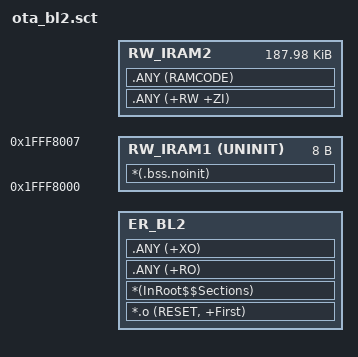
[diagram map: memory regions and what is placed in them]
#! armclang -E --target=arm-arm-none-eabi -mcpu=cortex-m4 -xc
#include "ota_layout.h"
LR_BL2 NTN_OTA_BL2_BASE NTN_OTA_BL2_SIZE {
    ER_BL2 NTN_OTA_BL2_BASE {
        *.o (RESET, +First)
        *(InRoot$$Sections)
        .ANY (+RO)
        .ANY (+XO)
    }
    RW_IRAM1 0x1FFF8000 UNINIT 0x8 {
        *(.bss.noinit)
    }
    RW_IRAM2 (NTN_OTA_MAILBOX + NTN_OTA_MAILBOX_SIZE) 0x2EFE8 {
        .ANY (+RW +ZI)
        .ANY (RAMCODE)
    }
}
